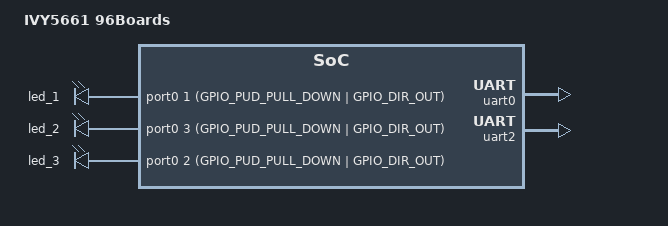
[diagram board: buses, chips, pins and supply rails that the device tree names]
/dts-v1/;

#include <unisoc/uwp5661.dtsi>
#include <dt-bindings/gpio/gpio.h>

/ {
	model = "IVY5661 96Boards";
	compatible = "unisoc,uwp5661", "unisoc,uwp566x", "unisoc,uwp";

	chosen {
		zephyr,sram = &sram0;
		zephyr,console = &uart0;
		zephyr,flash = &flash0;
	};

	leds {
		compatible = "gpio-leds";
		label = "led";
		led_1 {
			gpios = <&port0 1 (GPIO_PUD_PULL_DOWN | GPIO_DIR_OUT)>;
		};

		led_2 {
			gpios = <&port0 3 (GPIO_PUD_PULL_DOWN | GPIO_DIR_OUT)>;
		};

		led_3 {
			gpios = <&port0 2 (GPIO_PUD_PULL_DOWN | GPIO_DIR_OUT)>;
		};
	};
};

&uart0 {
	status = "ok";
};

&uart2 {
	status = "ok";
};

&flash0 {
	/*
	 * For more information, see:
	 * http://docs.zephyrproject.org/devices/dts/flash_partitions.html
	 */
	partitions {
		compatible = "fixed-partitions";
		#address-cells = <1>;
		#size-cells = <1>;

		boot_partition: partition@0 {
			label = "mcuboot";
			reg = <0x00000000 0xE000>;
		};
		scratch_partition: partition@E000 {
			label = "image-scratch";
			reg = <0x0000E000 0x2000>;
		};
		slot0_partition: partition@10000 {
			label = "image-0";
			reg = <0x00010000 0xC4000>;
		};
		slot1_partition: partition@188000 {
			label = "image-1";
			reg = <0x00188000 0xC4000>;
		};
		modem0_partition: partition@D4000 {
			label = "modem-0";
			reg = <0x000D4000 0xB4000>;
		};
		modem1_partition: partition@24C000 {
			label = "modem-1";
			reg = <0x0024C000 0xB4000>;
		};

#if defined(CONFIG_FILE_SYSTEM_NFFS)
		nffs_partition: partition@300000 {
			label = "nffs";
			reg = <0x000300000 0x00100000>;
		};
#endif

#if defined(CONFIG_FS_FLASH_STORAGE_PARTITION)
		storage_partition: partition@300000 {
			label = "storage";
			reg = <0x000300000 0x00100000>;
		};
#endif

	};
};
